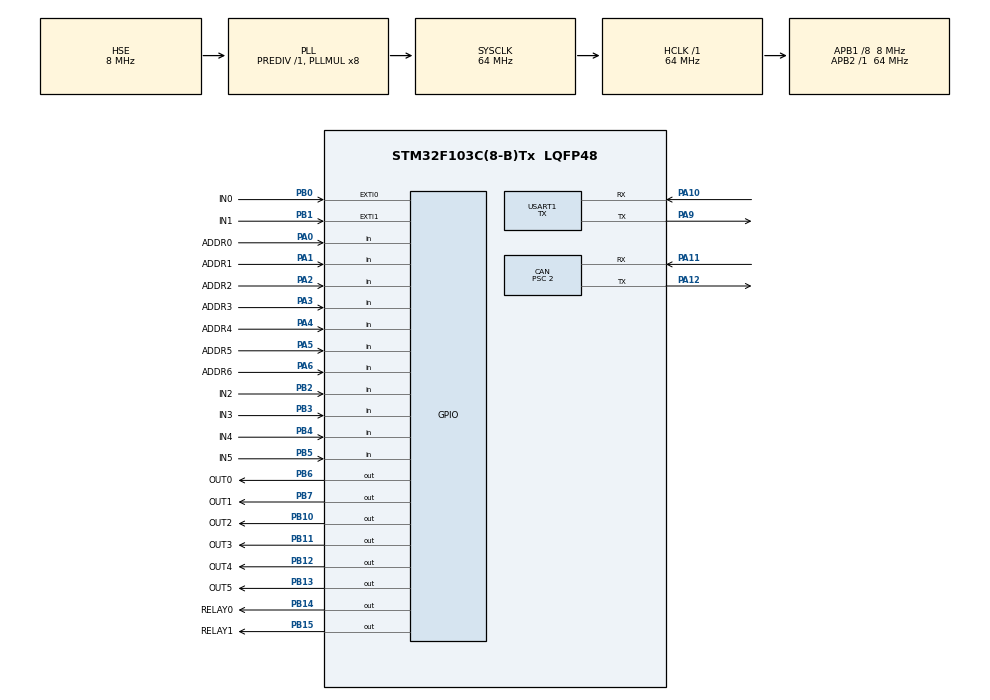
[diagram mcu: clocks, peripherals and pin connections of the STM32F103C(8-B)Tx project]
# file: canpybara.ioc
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CAN.ABOM=ENABLE
CAN.BS1=CAN_BS1_6TQ
CAN.BS2=CAN_BS2_1TQ
CAN.CalculateTimeBit=2000
CAN.CalculateTimeQuantum=250.0
CAN.Prescaler=2
IWDG.Prescaler=IWDG_PRESCALER_16
Mcu.Family=STM32F1
Mcu.Name=STM32F103C(8-B)Tx
Mcu.Package=LQFP48
NVIC.CAN1_RX1_IRQn=true\:0\:0\:false\:false\:true\:true
NVIC.CAN1_SCE_IRQn=true\:0\:0\:false\:false\:true\:true
NVIC.EXTI0_IRQn=true\:0\:0\:false\:false\:true\:true
NVIC.EXTI1_IRQn=true\:0\:0\:false\:false\:true\:true
NVIC.PriorityGroup=NVIC_PRIORITYGROUP_4
NVIC.RCC_IRQn=true\:0\:0\:false\:false\:true\:true
NVIC.TIM1_UP_IRQn=true\:0\:0\:false\:false\:true\:true
NVIC.TIM2_IRQn=true\:0\:0\:false\:false\:true\:true
NVIC.TIM3_IRQn=true\:0\:0\:false\:false\:true\:true
NVIC.USB_HP_CAN1_TX_IRQn=true\:0\:0\:false\:false\:true\:true
NVIC.USB_LP_CAN1_RX0_IRQn=true\:0\:0\:false\:false\:true\:true
PA0-WKUP.GPIO_Label=ADDR0
PA0-WKUP.GPIO_PuPd=GPIO_PULLUP
PA0-WKUP.Signal=GPIO_Input
PA1.GPIO_Label=ADDR1
PA1.GPIO_PuPd=GPIO_PULLUP
PA1.Signal=GPIO_Input
PA10.Mode=Asynchronous
PA10.Signal=USART1_RX
PA11.Mode=Master
PA11.Signal=CAN_RX
PA12.Mode=Master
PA12.Signal=CAN_TX
PA13.Mode=Serial_Wire
PA13.Signal=SYS_JTMS-SWDIO
PA14.Mode=Serial_Wire
PA14.Signal=SYS_JTCK-SWCLK
PA2.GPIO_Label=ADDR2
PA2.GPIO_PuPd=GPIO_PULLUP
PA2.Signal=GPIO_Input
PA3.GPIO_Label=ADDR3
PA3.GPIO_PuPd=GPIO_PULLUP
PA3.Signal=GPIO_Input
PA4.GPIO_Label=ADDR4
PA4.GPIO_PuPd=GPIO_PULLUP
PA4.Signal=GPIO_Input
PA5.GPIO_Label=ADDR5
PA5.GPIO_PuPd=GPIO_PULLUP
PA5.Signal=GPIO_Input
PA6.GPIO_Label=ADDR6
PA6.GPIO_PuPd=GPIO_PULLUP
PA6.Signal=GPIO_Input
PA9.Mode=Asynchronous
PA9.Signal=USART1_TX
PB0.GPIO_Label=IN0
PB0.GPIO_ModeDefaultEXTI=GPIO_MODE_IT_FALLING
PB0.Signal=GPXTI0
PB1.GPIO_Label=IN1
PB1.GPIO_ModeDefaultEXTI=GPIO_MODE_IT_FALLING
PB1.Signal=GPXTI1
PB10.GPIO_Label=OUT2
PB10.Signal=GPIO_Output
PB11.GPIO_Label=OUT3
PB11.Signal=GPIO_Output
PB12.GPIO_Label=OUT4
PB12.Signal=GPIO_Output
PB13.GPIO_Label=OUT5
PB13.Signal=GPIO_Output
PB14.GPIO_Label=RELAY0
PB14.Signal=GPIO_Output
PB15.GPIO_Label=RELAY1
PB15.Signal=GPIO_Output
PB2.GPIO_Label=IN2
PB2.Signal=GPIO_Input
PB3.GPIO_Label=IN3
PB3.Signal=GPIO_Input
PB4.GPIO_Label=IN4
PB4.Signal=GPIO_Input
PB5.GPIO_Label=IN5
PB5.Signal=GPIO_Input
PB6.GPIO_Label=OUT0
PB6.Signal=GPIO_Output
PB7.GPIO_Label=OUT1
PB7.Signal=GPIO_Output
PB8.Signal=I2C1_SCL
PB9.Signal=I2C1_SDA
PD0-OSC_IN.Mode=HSE-External-Oscillator
PD0-OSC_IN.Signal=RCC_OSC_IN
PD1-OSC_OUT.Mode=HSE-External-Oscillator
PD1-OSC_OUT.Signal=RCC_OSC_OUT
ProjectManager.HeapSize=0x200
ProjectManager.StackSize=0x400
ProjectManager.TargetToolchain=Makefile
RCC.AHBFreq_Value=64000000
RCC.APB1CLKDivider=RCC_HCLK_DIV8
RCC.APB1Freq_Value=8000000
RCC.APB1TimFreq_Value=16000000
RCC.APB2Freq_Value=64000000
RCC.APB2TimFreq_Value=64000000
RCC.EnbaleCSS=true
RCC.HCLKFreq_Value=64000000
RCC.PLLMUL=RCC_PLL_MUL8
RCC.PLLSourceVirtual=RCC_PLLSOURCE_HSE
RCC.SYSCLKFreq_VALUE=64000000
RCC.SYSCLKSource=RCC_SYSCLKSOURCE_PLLCLK
RCC.USBFreq_Value=64000000
TIM1.AutoReloadPreload=TIM_AUTORELOAD_PRELOAD_ENABLE
TIM1.Channel-Output\ Compare1\ No\ Output=TIM_CHANNEL_1
TIM1.ClockDivision=TIM_CLOCKDIVISION_DIV1
TIM1.CounterMode=TIM_COUNTERMODE_DOWN
TIM1.OCMode_1=TIM_OCMODE_TIMING
TIM1.Period=255
TIM1.Prescaler=60000
TIM1.TIM_MasterOutputTrigger=TIM_TRGO_UPDATE
TIM2.AutoReloadPreload=TIM_AUTORELOAD_PRELOAD_DISABLE
TIM2.Channel-Output\ Compare1\ No\ Output=TIM_CHANNEL_1
TIM2.ClockDivision=TIM_CLOCKDIVISION_DIV4
TIM2.CounterMode=TIM_COUNTERMODE_DOWN
TIM2.OCMode_1=TIM_OCMODE_TIMING
TIM2.Period=800
TIM2.Prescaler=10
TIM3.AutoReloadPreload=TIM_AUTORELOAD_PRELOAD_ENABLE
TIM3.Channel-Output\ Compare1\ No\ Output=TIM_CHANNEL_1
TIM3.ClockDivision=TIM_CLOCKDIVISION_DIV4
TIM3.CounterMode=TIM_COUNTERMODE_UP
TIM3.Period=500
TIM3.Prescaler=60000
USART1.Mode=MODE_TX
USART1.VirtualMode=VM_ASYNC
VP_IWDG_VS_IWDG.Mode=IWDG_Activate
VP_TIM1_VS_no_output1.Mode=Output Compare1 No Output
VP_TIM2_VS_no_output1.Mode=Output Compare1 No Output
VP_TIM3_VS_no_output1.Mode=Output Compare1 No Output
board=custom

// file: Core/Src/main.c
/**
  ******************************************************************************
  * @file           : main.c
  * @brief          : Main program body
  ******************************************************************************
  ** This notice applies to any and all portions of this file
  * that are not between comment pairs USER CODE BEGIN and
  * USER CODE END. Other portions of this file, whether
  * inserted by the user or by software development tools
  * are owned by their respective copyright owners.
  *
  * COPYRIGHT(c) 2019 STMicroelectronics
  *
  * Redistribution and use in source and binary forms, with or without modification,
  * are permitted provided that the following conditions are met:
  *   1. Redistributions of source code must retain the above copyright notice,
  *      this list of conditions and the following disclaimer.
  *   2. Redistributions in binary form must reproduce the above copyright notice,
  *      this list of conditions and the following disclaimer in the documentation
  *      and/or other materials provided with the distribution.
  *   3. Neither the name of STMicroelectronics nor the names of its contributors
  *      may be used to endorse or promote products derived from this software
  *      without specific prior written permission.
  *
  * THIS SOFTWARE IS PROVIDED BY THE COPYRIGHT HOLDERS AND CONTRIBUTORS "AS IS"
  * AND ANY EXPRESS OR IMPLIED WARRANTIES, INCLUDING, BUT NOT LIMITED TO, THE
  * IMPLIED WARRANTIES OF MERCHANTABILITY AND FITNESS FOR A PARTICULAR PURPOSE ARE
  * DISCLAIMED. IN NO EVENT SHALL THE COPYRIGHT HOLDER OR CONTRIBUTORS BE LIABLE
  * FOR ANY DIRECT, INDIRECT, INCIDENTAL, SPECIAL, EXEMPLARY, OR CONSEQUENTIAL
  * DAMAGES (INCLUDING, BUT NOT LIMITED TO, PROCUREMENT OF SUBSTITUTE GOODS OR
  * SERVICES; LOSS OF USE, DATA, OR PROFITS; OR BUSINESS INTERRUPTION) HOWEVER
  * CAUSED AND ON ANY THEORY OF LIABILITY, WHETHER IN CONTRACT, STRICT LIABILITY,
  * OR TORT (INCLUDING NEGLIGENCE OR OTHERWISE) ARISING IN ANY WAY OUT OF THE USE
  * OF THIS SOFTWARE, EVEN IF ADVISED OF THE POSSIBILITY OF SUCH DAMAGE.
  *
  ******************************************************************************
  */
#include "main.h"
#include "stm32f1xx_hal.h"

/* USER CODE BEGIN Includes */

#include "logger.h"
#include "can.h"
#include "test.h"
#include "wiegand.h"

/* USER CODE END Includes */

CAN_HandleTypeDef hcan;

IWDG_HandleTypeDef hiwdg;

TIM_HandleTypeDef htim1;
TIM_HandleTypeDef htim2;
TIM_HandleTypeDef htim3;

UART_HandleTypeDef huart1;

/* USER CODE BEGIN PV */
/* Private variables ---------------------------------------------------------*/

/* USER CODE END PV */

void SystemClock_Config(void);
static void MX_GPIO_Init(void);
static void MX_CAN_Init(void);
static void MX_USART1_UART_Init(void);
static void MX_IWDG_Init(void);
static void MX_TIM1_Init(void);
static void MX_TIM2_Init(void);
static void MX_TIM3_Init(void);

/* USER CODE BEGIN PFP */
/* Private function prototypes -----------------------------------------------*/

/* USER CODE END PFP */

int main(void)
{

  /* MCU Configuration----------------------------------------------------------*/

  /* Reset of all peripherals, Initializes the Flash interface and the Systick. */
  HAL_Init();

  /* Configure the system clock */
  SystemClock_Config();

  /* Initialize all configured peripherals */
  MX_GPIO_Init();
  MX_CAN_Init();
  MX_USART1_UART_Init();
  MX_IWDG_Init();
  MX_TIM1_Init();
  MX_TIM2_Init();
  MX_TIM3_Init();
  /* USER CODE BEGIN 2 */

  __enable_irq();

  LOG_BOOT();

  canpybara_can_init();

  // canpybara_test_sequence();

  HAL_TIM_Base_Start_IT(&htim1);
  HAL_TIM_Base_Start_IT(&htim2);
  /* USER CODE END 2 */

  /* Infinite loop */
  /* USER CODE BEGIN WHILE */
  for(;;)
  {
    HAL_IWDG_Refresh(&hiwdg);
    __asm__("WFI");
  /* USER CODE END WHILE */

  }

}

void SystemClock_Config(void)
{

  RCC_OscInitTypeDef RCC_OscInitStruct;
  RCC_ClkInitTypeDef RCC_ClkInitStruct;

    /**Initializes the CPU, AHB and APB busses clocks
    */
  RCC_OscInitStruct.OscillatorType = RCC_OSCILLATORTYPE_LSI|RCC_OSCILLATORTYPE_HSE;
  RCC_OscInitStruct.HSEState = RCC_HSE_ON;
  RCC_OscInitStruct.HSEPredivValue = RCC_HSE_PREDIV_DIV1;
  RCC_OscInitStruct.HSIState = RCC_HSI_ON;
  RCC_OscInitStruct.LSIState = RCC_LSI_ON;
  RCC_OscInitStruct.PLL.PLLState = RCC_PLL_ON;
  RCC_OscInitStruct.PLL.PLLSource = RCC_PLLSOURCE_HSE;
  RCC_OscInitStruct.PLL.PLLMUL = RCC_PLL_MUL8;
  if (HAL_RCC_OscConfig(&RCC_OscInitStruct) != HAL_OK)
  {
    _Error_Handler(__FILE__, __LINE__);
  }

    /**Initializes the CPU, AHB and APB busses clocks
    */
  RCC_ClkInitStruct.ClockType = RCC_CLOCKTYPE_HCLK|RCC_CLOCKTYPE_SYSCLK
                              |RCC_CLOCKTYPE_PCLK1|RCC_CLOCKTYPE_PCLK2;
  RCC_ClkInitStruct.SYSCLKSource = RCC_SYSCLKSOURCE_PLLCLK;
  RCC_ClkInitStruct.AHBCLKDivider = RCC_SYSCLK_DIV1;
  RCC_ClkInitStruct.APB1CLKDivider = RCC_HCLK_DIV8;
  RCC_ClkInitStruct.APB2CLKDivider = RCC_HCLK_DIV1;

  if (HAL_RCC_ClockConfig(&RCC_ClkInitStruct, FLASH_LATENCY_2) != HAL_OK)
  {
    _Error_Handler(__FILE__, __LINE__);
  }

    /**Enables the Clock Security System
    */
  HAL_RCC_EnableCSS();

    /**Configure the Systick interrupt time
    */
  HAL_SYSTICK_Config(HAL_RCC_GetHCLKFreq()/1000);

    /**Configure the Systick
    */
  HAL_SYSTICK_CLKSourceConfig(SYSTICK_CLKSOURCE_HCLK);

  /* SysTick_IRQn interrupt configuration */
  HAL_NVIC_SetPriority(SysTick_IRQn, 0, 0);
}

/* CAN init function */
static void MX_CAN_Init(void)
{

  hcan.Instance = CAN1;
  hcan.Init.Prescaler = 2;
  hcan.Init.Mode = CAN_MODE_NORMAL;
  hcan.Init.SJW = CAN_SJW_1TQ;
  hcan.Init.BS1 = CAN_BS1_6TQ;
  hcan.Init.BS2 = CAN_BS2_1TQ;
  hcan.Init.TTCM = DISABLE;
  hcan.Init.ABOM = ENABLE;
  hcan.Init.AWUM = DISABLE;
  hcan.Init.NART = DISABLE;
  hcan.Init.RFLM = DISABLE;
  hcan.Init.TXFP = DISABLE;
  if (HAL_CAN_Init(&hcan) != HAL_OK)
  {
    _Error_Handler(__FILE__, __LINE__);
  }

}

/* IWDG init function */
static void MX_IWDG_Init(void)
{

  hiwdg.Instance = IWDG;
  hiwdg.Init.Prescaler = IWDG_PRESCALER_16;
  hiwdg.Init.Reload = 4095;
  if (HAL_IWDG_Init(&hiwdg) != HAL_OK)
  {
    _Error_Handler(__FILE__, __LINE__);
  }

}

/* TIM1 init function */
static void MX_TIM1_Init(void)
{

  TIM_MasterConfigTypeDef sMasterConfig;
  TIM_OC_InitTypeDef sConfigOC;
  TIM_BreakDeadTimeConfigTypeDef sBreakDeadTimeConfig;

  htim1.Instance = TIM1;
  htim1.Init.Prescaler = 60000;
  htim1.Init.CounterMode = TIM_COUNTERMODE_DOWN;
  htim1.Init.Period = 255;
  htim1.Init.ClockDivision = TIM_CLOCKDIVISION_DIV1;
  htim1.Init.RepetitionCounter = 0;
  htim1.Init.AutoReloadPreload = TIM_AUTORELOAD_PRELOAD_ENABLE;
  if (HAL_TIM_OC_Init(&htim1) != HAL_OK)
  {
    _Error_Handler(__FILE__, __LINE__);
  }

  sMasterConfig.MasterOutputTrigger = TIM_TRGO_UPDATE;
  sMasterConfig.MasterSlaveMode = TIM_MASTERSLAVEMODE_DISABLE;
  if (HAL_TIMEx_MasterConfigSynchronization(&htim1, &sMasterConfig) != HAL_OK)
  {
    _Error_Handler(__FILE__, __LINE__);
  }

  sConfigOC.OCMode = TIM_OCMODE_TIMING;
  sConfigOC.Pulse = 0;
  sConfigOC.OCPolarity = TIM_OCPOLARITY_HIGH;
  sConfigOC.OCNPolarity = TIM_OCNPOLARITY_HIGH;
  sConfigOC.OCFastMode = TIM_OCFAST_DISABLE;
  sConfigOC.OCIdleState = TIM_OCIDLESTATE_RESET;
  sConfigOC.OCNIdleState = TIM_OCNIDLESTATE_RESET;
  if (HAL_TIM_OC_ConfigChannel(&htim1, &sConfigOC, TIM_CHANNEL_1) != HAL_OK)
  {
    _Error_Handler(__FILE__, __LINE__);
  }

  sBreakDeadTimeConfig.OffStateRunMode = TIM_OSSR_DISABLE;
  sBreakDeadTimeConfig.OffStateIDLEMode = TIM_OSSI_DISABLE;
  sBreakDeadTimeConfig.LockLevel = TIM_LOCKLEVEL_OFF;
  sBreakDeadTimeConfig.DeadTime = 0;
  sBreakDeadTimeConfig.BreakState = TIM_BREAK_DISABLE;
  sBreakDeadTimeConfig.BreakPolarity = TIM_BREAKPOLARITY_HIGH;
  sBreakDeadTimeConfig.AutomaticOutput = TIM_AUTOMATICOUTPUT_DISABLE;
  if (HAL_TIMEx_ConfigBreakDeadTime(&htim1, &sBreakDeadTimeConfig) != HAL_OK)
  {
    _Error_Handler(__FILE__, __LINE__);
  }

}

/* TIM2 init function */
static void MX_TIM2_Init(void)
{

  TIM_MasterConfigTypeDef sMasterConfig;
  TIM_OC_InitTypeDef sConfigOC;

  htim2.Instance = TIM2;
  htim2.Init.Prescaler = 10;
  htim2.Init.CounterMode = TIM_COUNTERMODE_DOWN;
  htim2.Init.Period = 800;
  htim2.Init.ClockDivision = TIM_CLOCKDIVISION_DIV4;
  htim2.Init.AutoReloadPreload = TIM_AUTORELOAD_PRELOAD_DISABLE;
  if (HAL_TIM_OC_Init(&htim2) != HAL_OK)
  {
    _Error_Handler(__FILE__, __LINE__);
  }

  sMasterConfig.MasterOutputTrigger = TIM_TRGO_RESET;
  sMasterConfig.MasterSlaveMode = TIM_MASTERSLAVEMODE_DISABLE;
  if (HAL_TIMEx_MasterConfigSynchronization(&htim2, &sMasterConfig) != HAL_OK)
  {
    _Error_Handler(__FILE__, __LINE__);
  }

  sConfigOC.OCMode = TIM_OCMODE_TIMING;
  sConfigOC.Pulse = 0;
  sConfigOC.OCPolarity = TIM_OCPOLARITY_HIGH;
  sConfigOC.OCFastMode = TIM_OCFAST_DISABLE;
  if (HAL_TIM_OC_ConfigChannel(&htim2, &sConfigOC, TIM_CHANNEL_1) != HAL_OK)
  {
    _Error_Handler(__FILE__, __LINE__);
  }

}

/* TIM3 init function */
static void MX_TIM3_Init(void)
{

  TIM_MasterConfigTypeDef sMasterConfig;
  TIM_OC_InitTypeDef sConfigOC;

  htim3.Instance = TIM3;
  htim3.Init.Prescaler = 60000;
  htim3.Init.CounterMode = TIM_COUNTERMODE_UP;
  htim3.Init.Period = 500;
  htim3.Init.ClockDivision = TIM_CLOCKDIVISION_DIV4;
  htim3.Init.AutoReloadPreload = TIM_AUTORELOAD_PRELOAD_ENABLE;
  if (HAL_TIM_OC_Init(&htim3) != HAL_OK)
  {
    _Error_Handler(__FILE__, __LINE__);
  }

  sMasterConfig.MasterOutputTrigger = TIM_TRGO_RESET;
  sMasterConfig.MasterSlaveMode = TIM_MASTERSLAVEMODE_DISABLE;
  if (HAL_TIMEx_MasterConfigSynchronization(&htim3, &sMasterConfig) != HAL_OK)
  {
    _Error_Handler(__FILE__, __LINE__);
  }

  sConfigOC.OCMode = TIM_OCMODE_TIMING;
  sConfigOC.Pulse = 0;
  sConfigOC.OCPolarity = TIM_OCPOLARITY_HIGH;
  sConfigOC.OCFastMode = TIM_OCFAST_DISABLE;
  if (HAL_TIM_OC_ConfigChannel(&htim3, &sConfigOC, TIM_CHANNEL_1) != HAL_OK)
  {
    _Error_Handler(__FILE__, __LINE__);
  }

}

/* USART1 init function */
static void MX_USART1_UART_Init(void)
{

  huart1.Instance = USART1;
  huart1.Init.BaudRate = 115200;
  huart1.Init.WordLength = UART_WORDLENGTH_8B;
  huart1.Init.StopBits = UART_STOPBITS_1;
  huart1.Init.Parity = UART_PARITY_NONE;
  huart1.Init.Mode = UART_MODE_TX;
  huart1.Init.HwFlowCtl = UART_HWCONTROL_NONE;
  huart1.Init.OverSampling = UART_OVERSAMPLING_16;
  if (HAL_UART_Init(&huart1) != HAL_OK)
  {
    _Error_Handler(__FILE__, __LINE__);
  }

}

/** Configure pins as
        * Analog
        * Input
        * Output
        * EVENT_OUT
        * EXTI
     PB8   ------> I2C1_SCL
     PB9   ------> I2C1_SDA
*/
static void MX_GPIO_Init(void)
{

  GPIO_InitTypeDef GPIO_InitStruct;

  /* GPIO Ports Clock Enable */
  __HAL_RCC_GPIOD_CLK_ENABLE();
  __HAL_RCC_GPIOA_CLK_ENABLE();
  __HAL_RCC_GPIOB_CLK_ENABLE();

  /*Configure GPIO pin Output Level */
  HAL_GPIO_WritePin(GPIOB, OUT2_Pin|OUT3_Pin|OUT4_Pin|OUT5_Pin
                          |RELAY0_Pin|RELAY1_Pin|OUT0_Pin|OUT1_Pin, GPIO_PIN_RESET);

  /*Configure GPIO pins : ADDR0_Pin ADDR1_Pin ADDR2_Pin ADDR3_Pin
                           ADDR4_Pin ADDR5_Pin ADDR6_Pin */
  GPIO_InitStruct.Pin = ADDR0_Pin|ADDR1_Pin|ADDR2_Pin|ADDR3_Pin
                          |ADDR4_Pin|ADDR5_Pin|ADDR6_Pin;
  GPIO_InitStruct.Mode = GPIO_MODE_INPUT;
  GPIO_InitStruct.Pull = GPIO_PULLUP;
  HAL_GPIO_Init(GPIOA, &GPIO_InitStruct);

  /*Configure GPIO pins : IN0_Pin IN1_Pin */
  GPIO_InitStruct.Pin = IN0_Pin|IN1_Pin;
  GPIO_InitStruct.Mode = GPIO_MODE_IT_FALLING;
  GPIO_InitStruct.Pull = GPIO_NOPULL;
  HAL_GPIO_Init(GPIOB, &GPIO_InitStruct);

  /*Configure GPIO pins : IN2_Pin IN3_Pin IN4_Pin IN5_Pin */
  GPIO_InitStruct.Pin = IN2_Pin|IN3_Pin|IN4_Pin|IN5_Pin;
  GPIO_InitStruct.Mode = GPIO_MODE_INPUT;
  GPIO_InitStruct.Pull = GPIO_NOPULL;
  HAL_GPIO_Init(GPIOB, &GPIO_InitStruct);

  /*Configure GPIO pins : OUT2_Pin OUT3_Pin OUT4_Pin OUT5_Pin
                           RELAY0_Pin RELAY1_Pin OUT0_Pin OUT1_Pin */
  GPIO_InitStruct.Pin = OUT2_Pin|OUT3_Pin|OUT4_Pin|OUT5_Pin
                          |RELAY0_Pin|RELAY1_Pin|OUT0_Pin|OUT1_Pin;
  GPIO_InitStruct.Mode = GPIO_MODE_OUTPUT_PP;
  GPIO_InitStruct.Pull = GPIO_NOPULL;
  GPIO_InitStruct.Speed = GPIO_SPEED_FREQ_LOW;
  HAL_GPIO_Init(GPIOB, &GPIO_InitStruct);

  /*Configure GPIO pins : PB8 PB9 */
  GPIO_InitStruct.Pin = GPIO_PIN_8|GPIO_PIN_9;
  GPIO_InitStruct.Mode = GPIO_MODE_AF_OD;
  GPIO_InitStruct.Speed = GPIO_SPEED_FREQ_HIGH;
  HAL_GPIO_Init(GPIOB, &GPIO_InitStruct);

  /*Configure peripheral I/O remapping */
  __HAL_AFIO_REMAP_I2C1_ENABLE();

  /* EXTI interrupt init*/
  HAL_NVIC_SetPriority(EXTI0_IRQn, 0, 0);
  HAL_NVIC_EnableIRQ(EXTI0_IRQn);

  HAL_NVIC_SetPriority(EXTI1_IRQn, 0, 0);
  HAL_NVIC_EnableIRQ(EXTI1_IRQn);

}

void _Error_Handler(char *file, int line)
{
  /* USER CODE BEGIN Error_Handler_Debug */

  LOG("ERROR HANDLER -> %s:%d", file, line);

  /* User can add his own implementation to report the HAL error return state */
  while(1)
  {
  }
  /* USER CODE END Error_Handler_Debug */
}

/************************ (C) COPYRIGHT STMicroelectronics *****END OF FILE****/
